# STM32F413CGU3 register map
File version: 1.0
Registers are 32-bit, access not given, reset 0x0 unless marked. A register's access mark holds for its fields unless they carry their own. Offsets are from the block's base; [hi:lo] are bit positions; {n}, {i} and the like mark numbered series; 'fields as' and 'values as' point back to an identical list.

## SYSCFG
Base 0x40013800
0x00 MEMRMP
  [1:0] MEM_MODE
0x04 PMC
{0x4+4i} EXTICR{i} (i=1..4)
0x1C CFGR2
0x20 CMPCR
0x2C CFGR
  [0] 0I2CFMP1_SCL
0x30 MCHDLYCR

## EXTI
Base 0x40013C00
0x00 IMR
0x04 EMR
0x08 RTSR
0x0C FTSR
0x10 SWIER
0x14 PR

## SAI1
Base 0x40015800
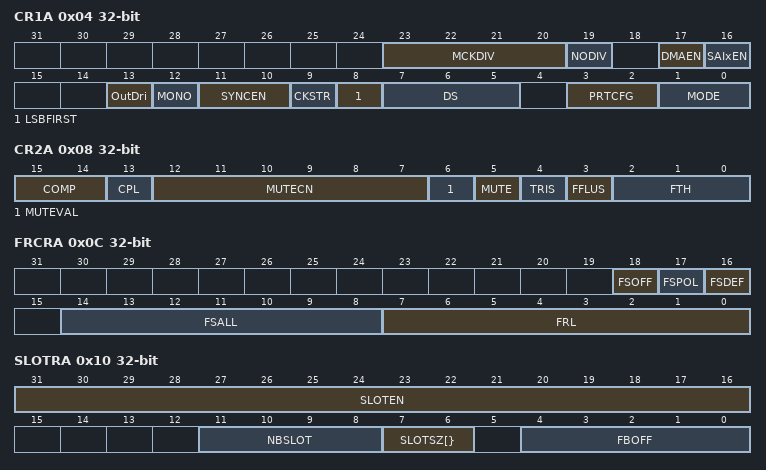
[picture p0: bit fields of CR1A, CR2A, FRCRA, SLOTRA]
0x04 CR1A
  [23:20] MCKDIV, [19] NODIV, [17] DMAEN, [16] SAIxEN, [13] OutDri, [12] MONO, [11:10] SYNCEN, [9] CKSTR, [8] LSBFIRST, [7:5] DS, [3:2] PRTCFG, [1:0] MODE
0x08 CR2A
  [15:14] COMP, [13] CPL, [12:7] MUTECN, [6] MUTEVAL, [5] MUTE, [4] TRIS, [3] FFLUS, [2:0] FTH
0x0C FRCRA
  [18] FSOFF, [17] FSPOL, [16] FSDEF, [14:8] FSALL, [7:0] FRL
0x10 SLOTRA
  [31:16] SLOTEN, [11:8] NBSLOT, [7:6] SLOTSZ[}, [4:0] FBOFF
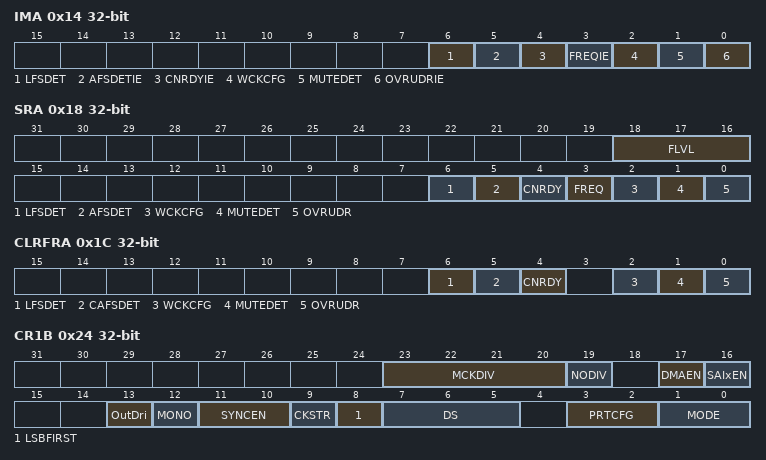
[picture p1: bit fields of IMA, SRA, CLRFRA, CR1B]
0x14 IMA
  [6] LFSDET, [5] AFSDETIE, [4] CNRDYIE, [3] FREQIE, [2] WCKCFG, [1] MUTEDET, [0] OVRUDRIE
0x18 SRA
  [18:16] FLVL, [6] LFSDET, [5] AFSDET, [4] CNRDY, [3] FREQ, [2] WCKCFG, [1] MUTEDET, [0] OVRUDR
0x1C CLRFRA
  [6] LFSDET, [5] CAFSDET, [4] CNRDY, [2] WCKCFG, [1] MUTEDET, [0] OVRUDR
0x20 DRA
  [31:0] DATA
0x24 CR1B
  fields as CR1A
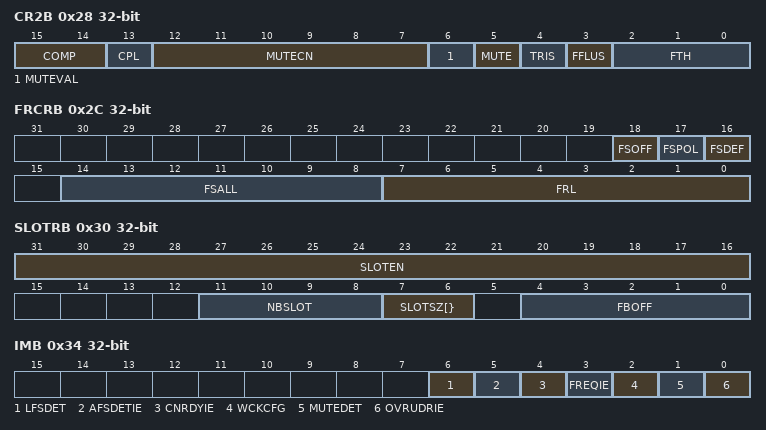
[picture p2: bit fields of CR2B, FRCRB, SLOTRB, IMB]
0x28 CR2B
  fields as CR2A
0x2C FRCRB
  [18] FSOFF, [17] FSPOL, [16] FSDEF, [14:8] FSALL, [7:0] FRL
0x30 SLOTRB
  [31:16] SLOTEN, [11:8] NBSLOT, [7:6] SLOTSZ[}, [4:0] FBOFF
0x34 IMB
  fields as IMA
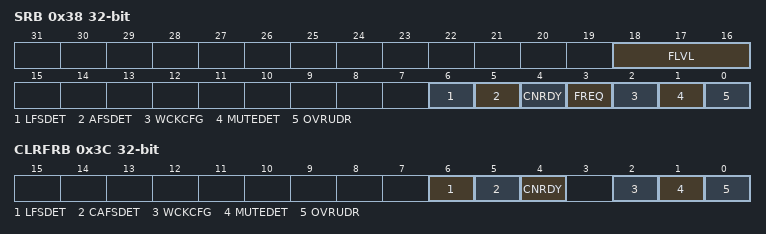
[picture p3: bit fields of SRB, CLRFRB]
0x38 SRB
  fields as SRA
0x3C CLRFRB
  fields as CLRFRA
0x40 DRB
  [31:0] DATA

## DFSDM1
Base 0x40016000
Same registers: DFSDM2 0x40016400
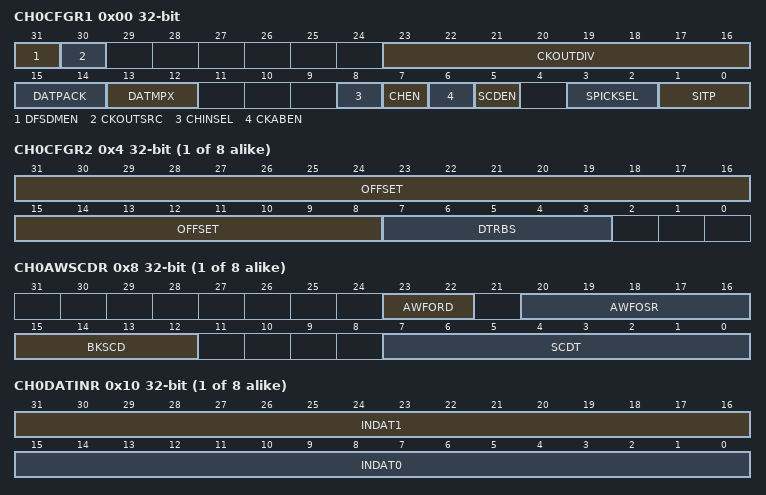
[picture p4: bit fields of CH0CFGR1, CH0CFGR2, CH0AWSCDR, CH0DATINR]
0x00 CH0CFGR1
  [31] DFSDMEN, [30] CKOUTSRC, [23:16] CKOUTDIV, [15:14] DATPACK, [13:12] DATMPX, [8] CHINSEL, [7] CHEN, [6] CKABEN, [5] SCDEN, [3:2] SPICKSEL, [1:0] SITP
{0x4+0x20*i} CH{i}CFGR2 (i=0..7)
  [31:8] OFFSET, [7:3] DTRBS
{0x8+0x20*i} CH{i}AWSCDR (i=0..7)
  [23:22] AWFORD, [20:16] AWFOSR, [15:12] BKSCD, [7:0] SCDT
{0xC+0x20*i} CH{i}WDATR (i=0..7)
  [15:0] WDATA
{0x10+0x20*i} CH{i}DATINR (i=0..7)
  [31:16] INDAT1, [15:0] INDAT0
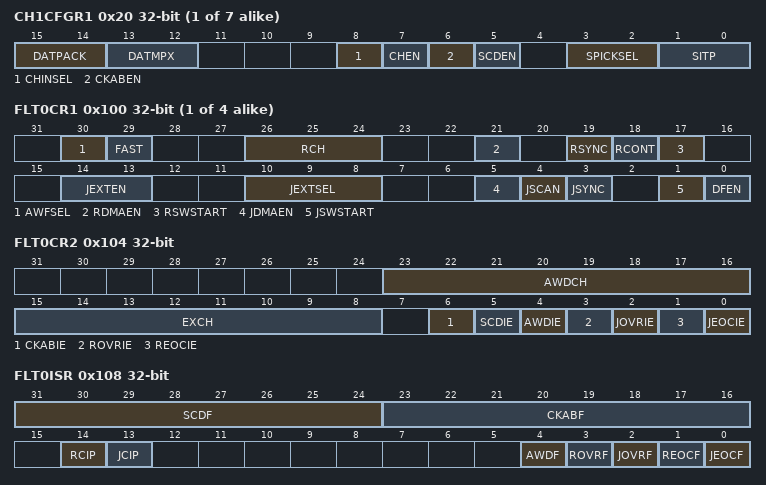
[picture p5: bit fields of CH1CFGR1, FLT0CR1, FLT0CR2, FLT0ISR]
{0x0+0x20*i} CH{i}CFGR1 (i=1..7)
  [15:14] DATPACK, [13:12] DATMPX, [8] CHINSEL, [7] CHEN, [6] CKABEN, [5] SCDEN, [3:2] SPICKSEL, [1:0] SITP
{0x100+0x80*i} FLT{i}CR1 (i=0..3)
  [30] AWFSEL, [29] FAST, [26:24] RCH, [21] RDMAEN, [19] RSYNC, [18] RCONT, [17] RSWSTART, [14:13] JEXTEN, [10:8] JEXTSEL, [5] JDMAEN, [4] JSCAN, [3] JSYNC, [1] JSWSTART, [0] DFEN
0x104 FLT0CR2
  [23:16] AWDCH, [15:8] EXCH, [6] CKABIE, [5] SCDIE, [4] AWDIE, [3] ROVRIE, [2] JOVRIE, [1] REOCIE, [0] JEOCIE
0x108 FLT0ISR
  [31:24] SCDF, [23:16] CKABF, [14] RCIP, [13] JCIP, [4] AWDF, [3] ROVRF, [2] JOVRF, [1] REOCF, [0] JEOCF
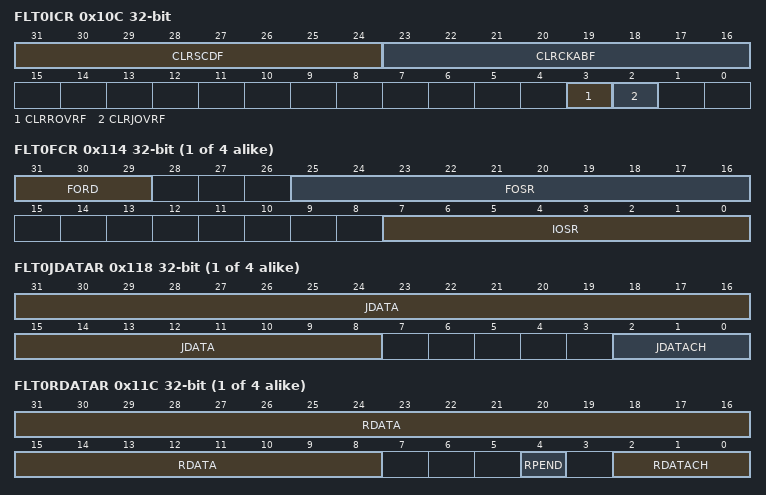
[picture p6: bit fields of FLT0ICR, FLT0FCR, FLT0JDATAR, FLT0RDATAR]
0x10C FLT0ICR
  [31:24] CLRSCDF, [23:16] CLRCKABF, [3] CLRROVRF, [2] CLRJOVRF
{0x110+0x80*i} FLT{i}JCHGR (i=0..3)
  [7:0] JCHG
{0x114+0x80*i} FLT{i}FCR (i=0..3)
  [31:29] FORD, [25:16] FOSR, [7:0] IOSR
{0x118+0x80*i} FLT{i}JDATAR (i=0..3)
  [31:8] JDATA, [2:0] JDATACH
{0x11C+0x80*i} FLT{i}RDATAR (i=0..3)
  [31:8] RDATA, [4] RPEND, [2:0] RDATACH
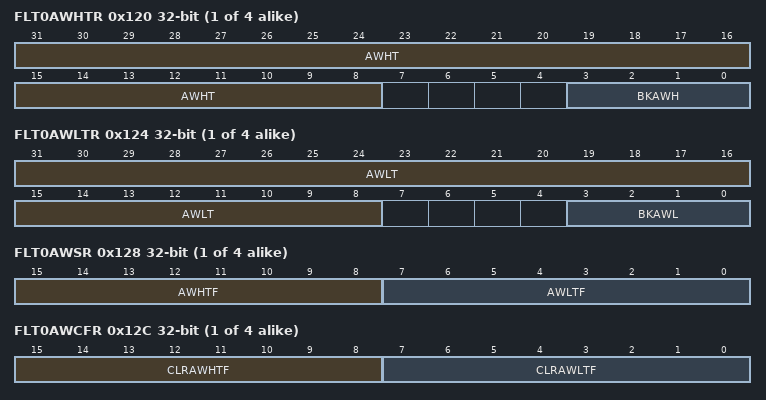
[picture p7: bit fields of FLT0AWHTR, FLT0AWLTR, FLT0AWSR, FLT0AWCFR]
{0x120+0x80*i} FLT{i}AWHTR (i=0..3)
  [31:8] AWHT, [3:0] BKAWH
{0x124+0x80*i} FLT{i}AWLTR (i=0..3)
  [31:8] AWLT, [3:0] BKAWL
{0x128+0x80*i} FLT{i}AWSR (i=0..3)
  [15:8] AWHTF, [7:0] AWLTF
{0x12C+0x80*i} FLT{i}AWCFR (i=0..3)
  [15:8] CLRAWHTF, [7:0] CLRAWLTF
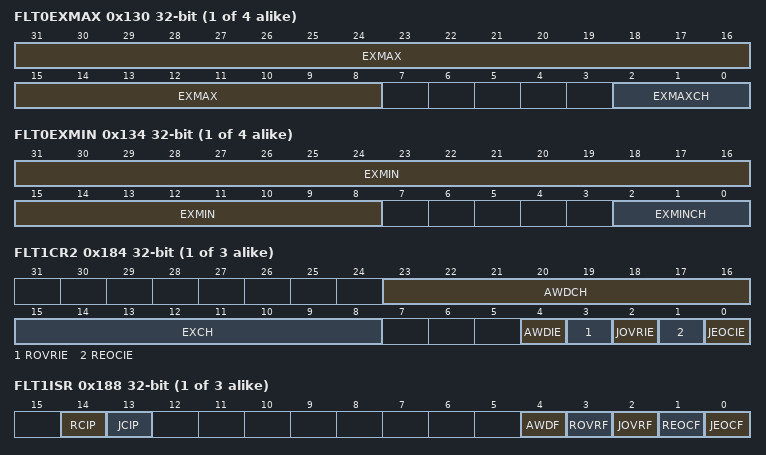
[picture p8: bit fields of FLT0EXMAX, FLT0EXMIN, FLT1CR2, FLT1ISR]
{0x130+0x80*i} FLT{i}EXMAX (i=0..3)
  [31:8] EXMAX, [2:0] EXMAXCH
{0x134+0x80*i} FLT{i}EXMIN (i=0..3)
  [31:8] EXMIN, [2:0] EXMINCH
{0x138+0x80*i} FLT{i}CNVTIMR (i=0..3)
  [31:4] CNVCNT
{0x104+0x80*i} FLT{i}CR2 (i=1..3)
  [23:16] AWDCH, [15:8] EXCH, [4] AWDIE, [3] ROVRIE, [2] JOVRIE, [1] REOCIE, [0] JEOCIE
{0x108+0x80*i} FLT{i}ISR (i=1..3)
  [14] RCIP, [13] JCIP, [4] AWDF, [3] ROVRF, [2] JOVRF, [1] REOCF, [0] JEOCF
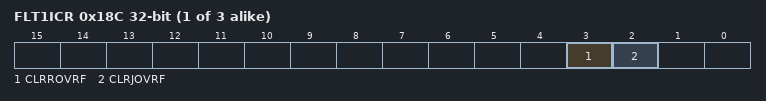
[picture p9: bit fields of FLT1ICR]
{0x10C+0x80*i} FLT{i}ICR (i=1..3)
  [3] CLRROVRF, [2] CLRJOVRF

## GPIOA
Base 0x40020000
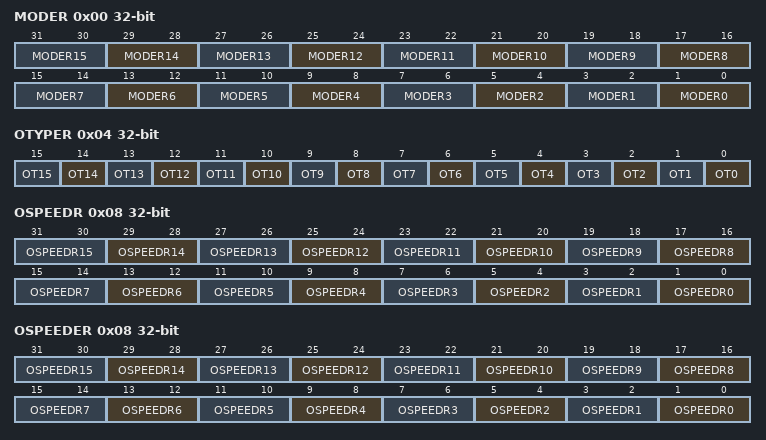
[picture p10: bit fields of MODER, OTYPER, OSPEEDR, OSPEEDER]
0x00 MODER
  [2n+1:2n] MODER{n} (n=0..15)
0x04 OTYPER
  [n] OT{n} (n=0..15)
0x08 OSPEEDR
  [2n+1:2n] OSPEEDR{n} (n=0..15)
0x08 OSPEEDER
  [2n+1:2n] OSPEEDR{n} (n=0..15)
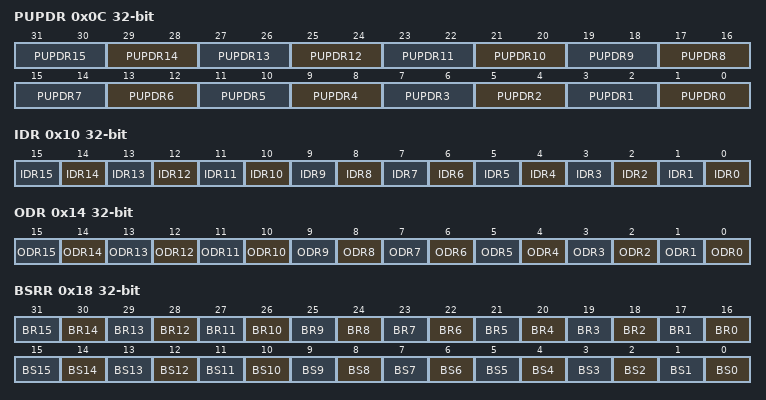
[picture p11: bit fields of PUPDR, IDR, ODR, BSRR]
0x0C PUPDR
  [2n+1:2n] PUPDR{n} (n=0..15)
0x10 IDR
  [n] IDR{n} (n=0..15)
0x14 ODR
  [n] ODR{n} (n=0..15)
0x18 BSRR
  [n+16] BR{n} (n=0..15), [n] BS{n} (n=0..15)
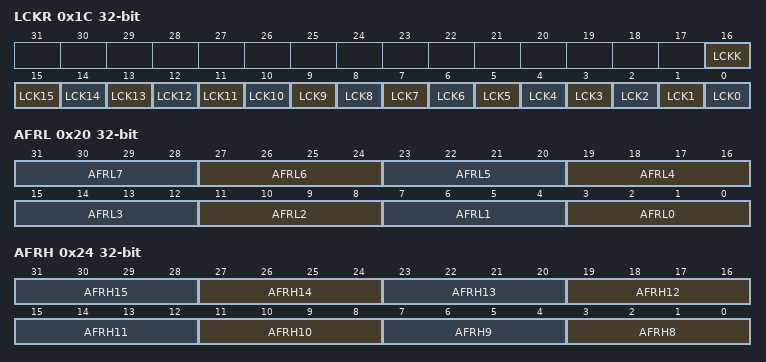
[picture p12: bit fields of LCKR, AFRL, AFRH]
0x1C LCKR
  [16] LCKK, [n] LCK{n} (n=0..15)
0x20 AFRL
  [4n+3:4n] AFRL{n} (n=0..7)
0x24 AFRH
  [4n-29:4n-32] AFRH{n} (n=8..15)

## GPIOB
Base 0x40020400
Registers as GPIOA, without OSPEEDER.

## GPIOC
Base 0x40020800
Registers as GPIOA, without OSPEEDER.

## GPIOD
Base 0x40020C00
Registers as GPIOA, without OSPEEDER.

## GPIOE
Base 0x40021000
Registers as GPIOA, without OSPEEDER.

## GPIOF
Base 0x40021400
Registers as GPIOA, without OSPEEDER.

## GPIOG
Base 0x40021800
Registers as GPIOA, without OSPEEDER.

## GPIOH
Base 0x40021C00
Registers as GPIOA, without OSPEEDER.
